# APM32F403 register map
File version: 1.0
CPU: CM4 r1p0, little endian, no MPU, no FPU, 4 interrupt priority bits
Registers are 32-bit, read-write, reset 0x0 unless marked. A register's access mark holds for its fields unless they carry their own. Offsets are from the block's base; [hi:lo] are bit positions; {n}, {i} and the like mark numbered series; 'fields as' and 'values as' point back to an identical list.

## RTC — Real-time clock
Base 0x40002800
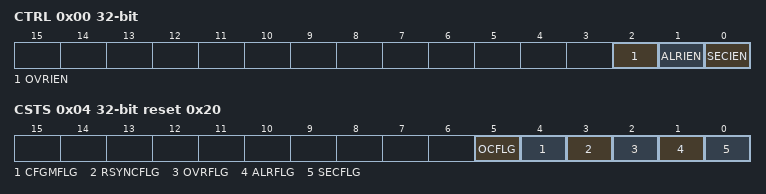
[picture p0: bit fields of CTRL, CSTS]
0x00 CTRL — Control register
  [2] OVRIEN — Overflow interrupt Enable
  [1] ALRIEN — Alarm interrupt Enable
  [0] SECIEN — Second interrupt Enable
0x04 CSTS access per field reset 0x20 — Control and State register
  [5] OCFLG ro — RTC Operation Complete Flag
  [4] CFGMFLG rw — Configure Mode Enable Flag
  [3] RSYNCFLG rw — Registers Synchronized Flag
  [2] OVRFLG rw — Overflow Occur Flag
  [1] ALRFLG rw — Alarm Occur Flag
  [0] SECFLG rw — Second Flag
0x08 PSCRLDH wo — RTC predivision loading register High Bit
  [3:0] PSCRLDH — RTC Prescaler Load Register High
0x0C PSCRLDL wo reset 0x8000 — RTC predivision loading register Low Bit
  [15:0] PSCRLDL — RTC Prescaler Divider Register Low
0x10 PSCH ro — RTC predivider remainder register High Bit
  [3:0] PSCH — RTC prescaler divider register high
0x14 PSCL ro reset 0x8000 — RTC predivider remainder register Low Bit
  [15:0] PSCL — RTC prescaler divider register Low
0x18 CNTH — RTC count register High Bit
  [15:0] CNTH — RTC counter register high
0x1C CNTL — RTC count register Low Bit
  [15:0] CNTL — RTC counter register Low
0x20 ALRH wo reset 0xFFFF — RTC alarm clock register High Bit
  [15:0] ALRH — RTC alarm register high
0x24 ALRL wo reset 0xFFFF — RTC alarm clock register Low Bit
  [15:0] ALRL — RTC alarm register low

## BAKPR — Real-time clock
Base 0x40006C00
{0x0+4i} DATA{i} (i=1..10) — Bakpr data register (BAKPR_DATA)
  [15:0] DATA — User Backup Data
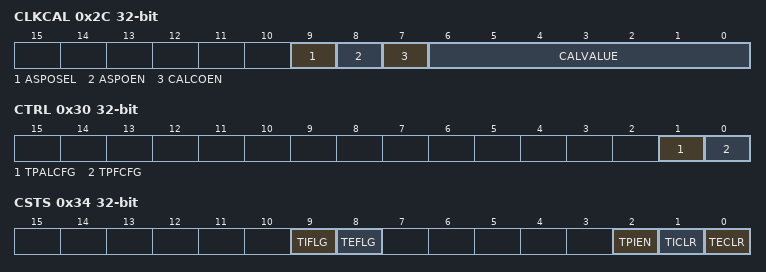
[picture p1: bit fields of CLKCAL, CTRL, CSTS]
0x2C CLKCAL — RTC clock calibration register (BAKPR_CLKCAL)
  [9] ASPOSEL — Alarm or second output selection
  [8] ASPOEN — Alarm or second output enable
  [7] CALCOEN — Calibration Clock Output
  [6:0] CALVALUE — Calibration value
0x30 CTRL — Bakr control register (BAKPR_CTRL)
  [1] TPALCFG — Tamper pin active level
  [0] TPFCFG — Tamper pin enable
0x34 CSTS access per field — Bakr control/status register (BAKPR_CSTS)
  [9] TIFLG ro — Tamper Interrupt Flag
  [8] TEFLG ro — Tamper Event Flag
  [2] TPIEN rw — Tamper Pin interrupt enable
  [1] TICLR wo — Clear Tamper Interrupt
  [0] TECLR wo — Clear Tamper event
{0x14+4i} DATA{i} (i=11..42) — Bakpr data register (BAKPR_DATA)
  [15:0] DATA — User Backup Data

## EINT — External interrupt/event controller
Base 0x40010400
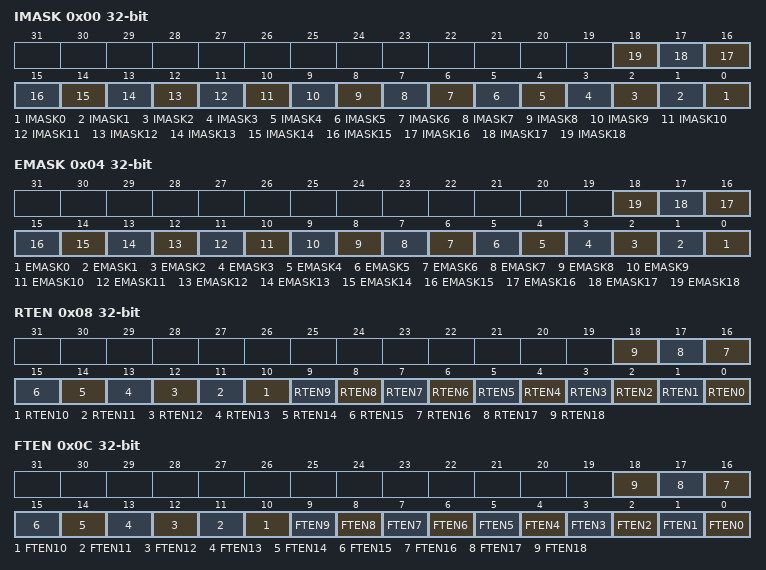
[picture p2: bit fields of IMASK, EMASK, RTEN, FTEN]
0x00 IMASK — Interrupt mask register
  [n] IMASK{n} (n=0..18) — Interrupt Mask on line {n}
0x04 EMASK — Event mask register
  [n] EMASK{n} (n=0..18) — Event Mask on line {n}
0x08 RTEN — Rising Trigger selection register
  [n] RTEN{n} (n=0..18) — Rising trigger event configuration of line {n}
0x0C FTEN — Falling Trigger selection register
  [n] FTEN{n} (n=0..18) — Falling trigger event configuration of line {n}
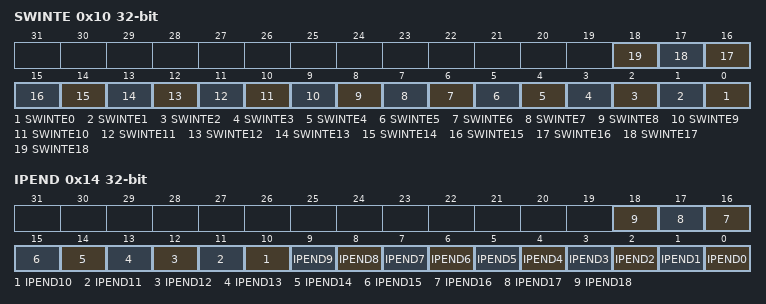
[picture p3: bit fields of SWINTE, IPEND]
0x10 SWINTE — Software interrupt event register
  [n] SWINTE{n} (n=0..18) — Software Interrupt on line {n}
0x14 IPEND — Pending register
  [n] IPEND{n} (n=0..18) — Pending bit {n}

## NVIC — Nested Vectored Interrupt Controller
Base 0xE000E100
{0x0+4i} ISER{i} (i=0..2) — Interrupt Set-Enable Register
  [31:0] SETENA
{0x80+4i} ICER{i} (i=0..2) — Interrupt Clear-Enable Register
  [31:0] CLRENA
{0x100+4i} ISPR{i} (i=0..2) — Interrupt Set-Pending Register
  [31:0] SETPEND
{0x180+4i} ICPR{i} (i=0..2) — Interrupt Clear-Pending Register
  [31:0] CLRPEND
{0x200+4i} IABR{i} ro (i=0..2) — Interrupt Active Bit Register
  [31:0] ACTIVE
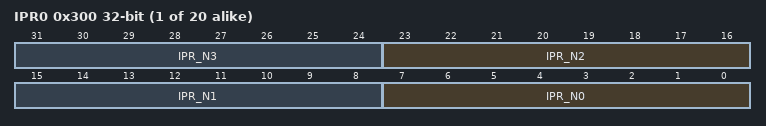
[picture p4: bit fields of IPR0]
{0x300+4i} IPR{i} (i=0..19) — Interrupt Priority Register
  [8n+7:8n] IPR_N{n} (n=0..3)

## OTG_FS_HOST — USB on the go full speed
Base 0x50000400
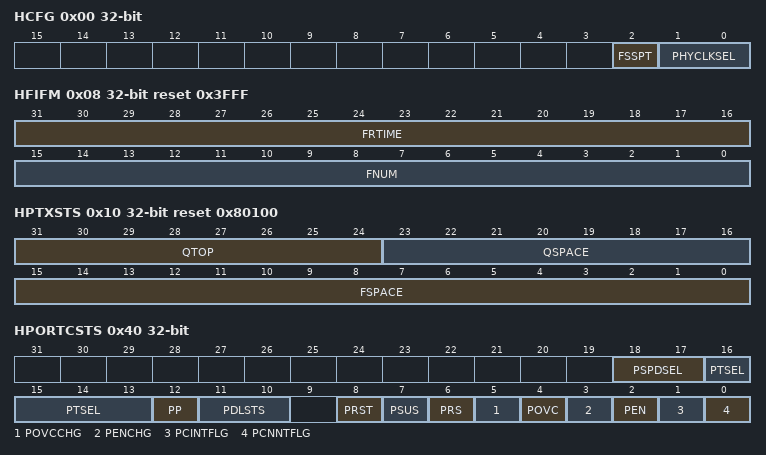
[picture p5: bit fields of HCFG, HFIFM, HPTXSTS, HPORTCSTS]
0x00 HCFG access per field — OTG_FS host configuration register (OTG_FS_HCFG)
  [2] FSSPT ro — FS- and LS-only support
  [1:0] PHYCLKSEL rw — FS/LS PHY clock select
0x04 HFIVL reset 0xEA60 — OTG_FS Host frame interval register
  [15:0] FIVL — Frame interval
0x08 HFIFM ro reset 0x3FFF — OTG_FS host frame number/frame time remaining register (OTG_FS_HFNUM)
  [31:16] FRTIME — Frame time remaining
  [15:0] FNUM — Frame number
0x10 HPTXSTS access per field reset 0x80100 — OTG_FS_Host periodic transmit FIFO/queue status register (OTG_FS_HPTXSTS)
  [31:24] QTOP ro — Top of the periodic transmit request queue
  [23:16] QSPACE ro — Periodic transmit request queue space available
  [15:0] FSPACE rw — Periodic transmit data FIFO space available
0x14 HACHINT ro — OTG_FS Host all channels interrupt register
  [15:0] ACHINT — Channel interrupts
0x18 HACHIMASK — OTG_FS host all channels interrupt mask register
  [15:0] ACHIMASK — Channel interrupt mask
0x40 HPORTCSTS access per field — OTG_FS host port control and status register (OTG_FS_HPRT)
  [18:17] PSPDSEL ro — Port speed
  [16:13] PTSEL rw — Port test control
  [12] PP rw — Port power
  [11:10] PDLSTS ro — Port line status
  [8] PRST rw — Port reset
  [7] PSUS rw — Port suspend
  [6] PRS rw — Port resume
  [5] POVCCHG rw — Port overcurrent change
  [4] POVC ro — Port overcurrent active
  [3] PENCHG rw — Port enable/disable change
  [2] PEN rw — Port enable
  [1] PCINTFLG rw — Port connect detected
  [0] PCNNTFLG ro — Port connect status
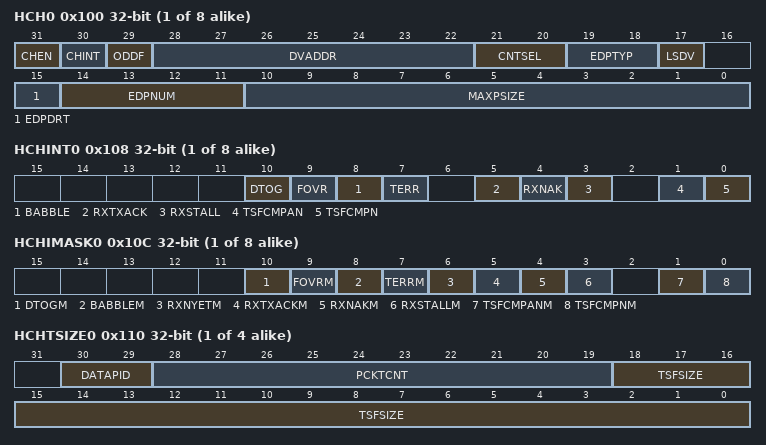
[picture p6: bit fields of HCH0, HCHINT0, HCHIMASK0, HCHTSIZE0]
{0x100+0x20*i} HCH{i} (i=0..7) — OTG_FS host channel-{i} characteristics register (OTG_FS_HCCHAR{i})
  [31] CHEN — Channel enable
  [30] CHINT — Channel disable
  [29] ODDF — Odd frame
  [28:22] DVADDR — Device address
  [21:20] CNTSEL — Multicount
  [19:18] EDPTYP — Endpoint type
  [17] LSDV — Low-speed device
  [15] EDPDRT — Endpoint direction
  [14:11] EDPNUM — Endpoint number
  [10:0] MAXPSIZE — Maximum packet size
{0x108+0x20*i} HCHINT{i} (i=0..7) — OTG_FS host channel-{i} interrupt register (OTG_FS_HCINT{i})
  [10] DTOG — Data toggle error
  [9] FOVR — Frame overrun
  [8] BABBLE — Babble error
  [7] TERR — Transaction error
  [5] RXTXACK — ACK response received/transmitted interrupt
  [4] RXNAK — NAK response received interrupt
  [3] RXSTALL — STALL response received interrupt
  [1] TSFCMPAN — Channel halted
  [0] TSFCMPN — Transfer completed
{0x10C+0x20*i} HCHIMASK{i} (i=0..7) — OTG_FS host channel-{i} mask register (OTG_FS_HCINTMSK{i})
  [10] DTOGM — Data toggle error mask
  [9] FOVRM — Frame overrun mask
  [8] BABBLEM — Babble error mask
  [7] TERRM — Transaction error mask
  [6] RXNYETM — response received interrupt mask
  [5] RXTXACKM — ACK response received/transmitted interrupt mask
  [4] RXNAKM — NAK response received interrupt mask
  [3] RXSTALLM — STALL response received interrupt mask
  [1] TSFCMPANM — Channel halted mask
  [0] TSFCMPNM — Transfer completed mask
{0x110+0x20*i} HCHTSIZE{i} (i=0..3) — OTG_FS host channel-{i} transfer size register
  [30:29] DATAPID
  [28:19] PCKTCNT — Packet count
  [18:0] TSFSIZE — Transfer size
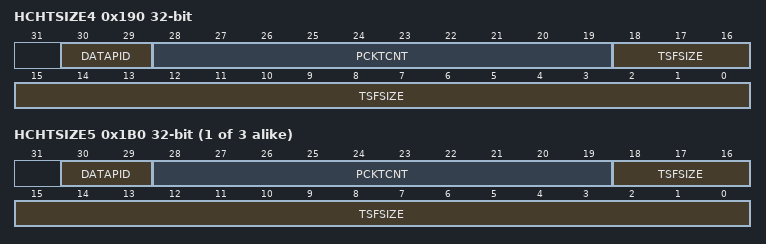
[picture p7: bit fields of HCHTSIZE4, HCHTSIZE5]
0x190 HCHTSIZE4 — OTG_FS host channel-x transfer size register
  fields as HCHTSIZE0
{0x110+0x20*i} HCHTSIZE{i} (i=5..7) — OTG_FS host channel-{i} transfer size register
  fields as HCHTSIZE0

## OTG_FS_PWRCLK — USB on the go full speed
Base 0x50000E00
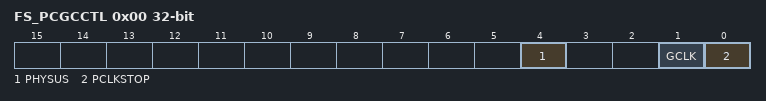
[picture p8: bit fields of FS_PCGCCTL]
0x00 FS_PCGCCTL — OTG_FS power and clock gating control register
  [4] PHYSUS — PHY Suspended
  [1] GCLK — Gate HCLK
  [0] PCLKSTOP — Stop PHY clock
